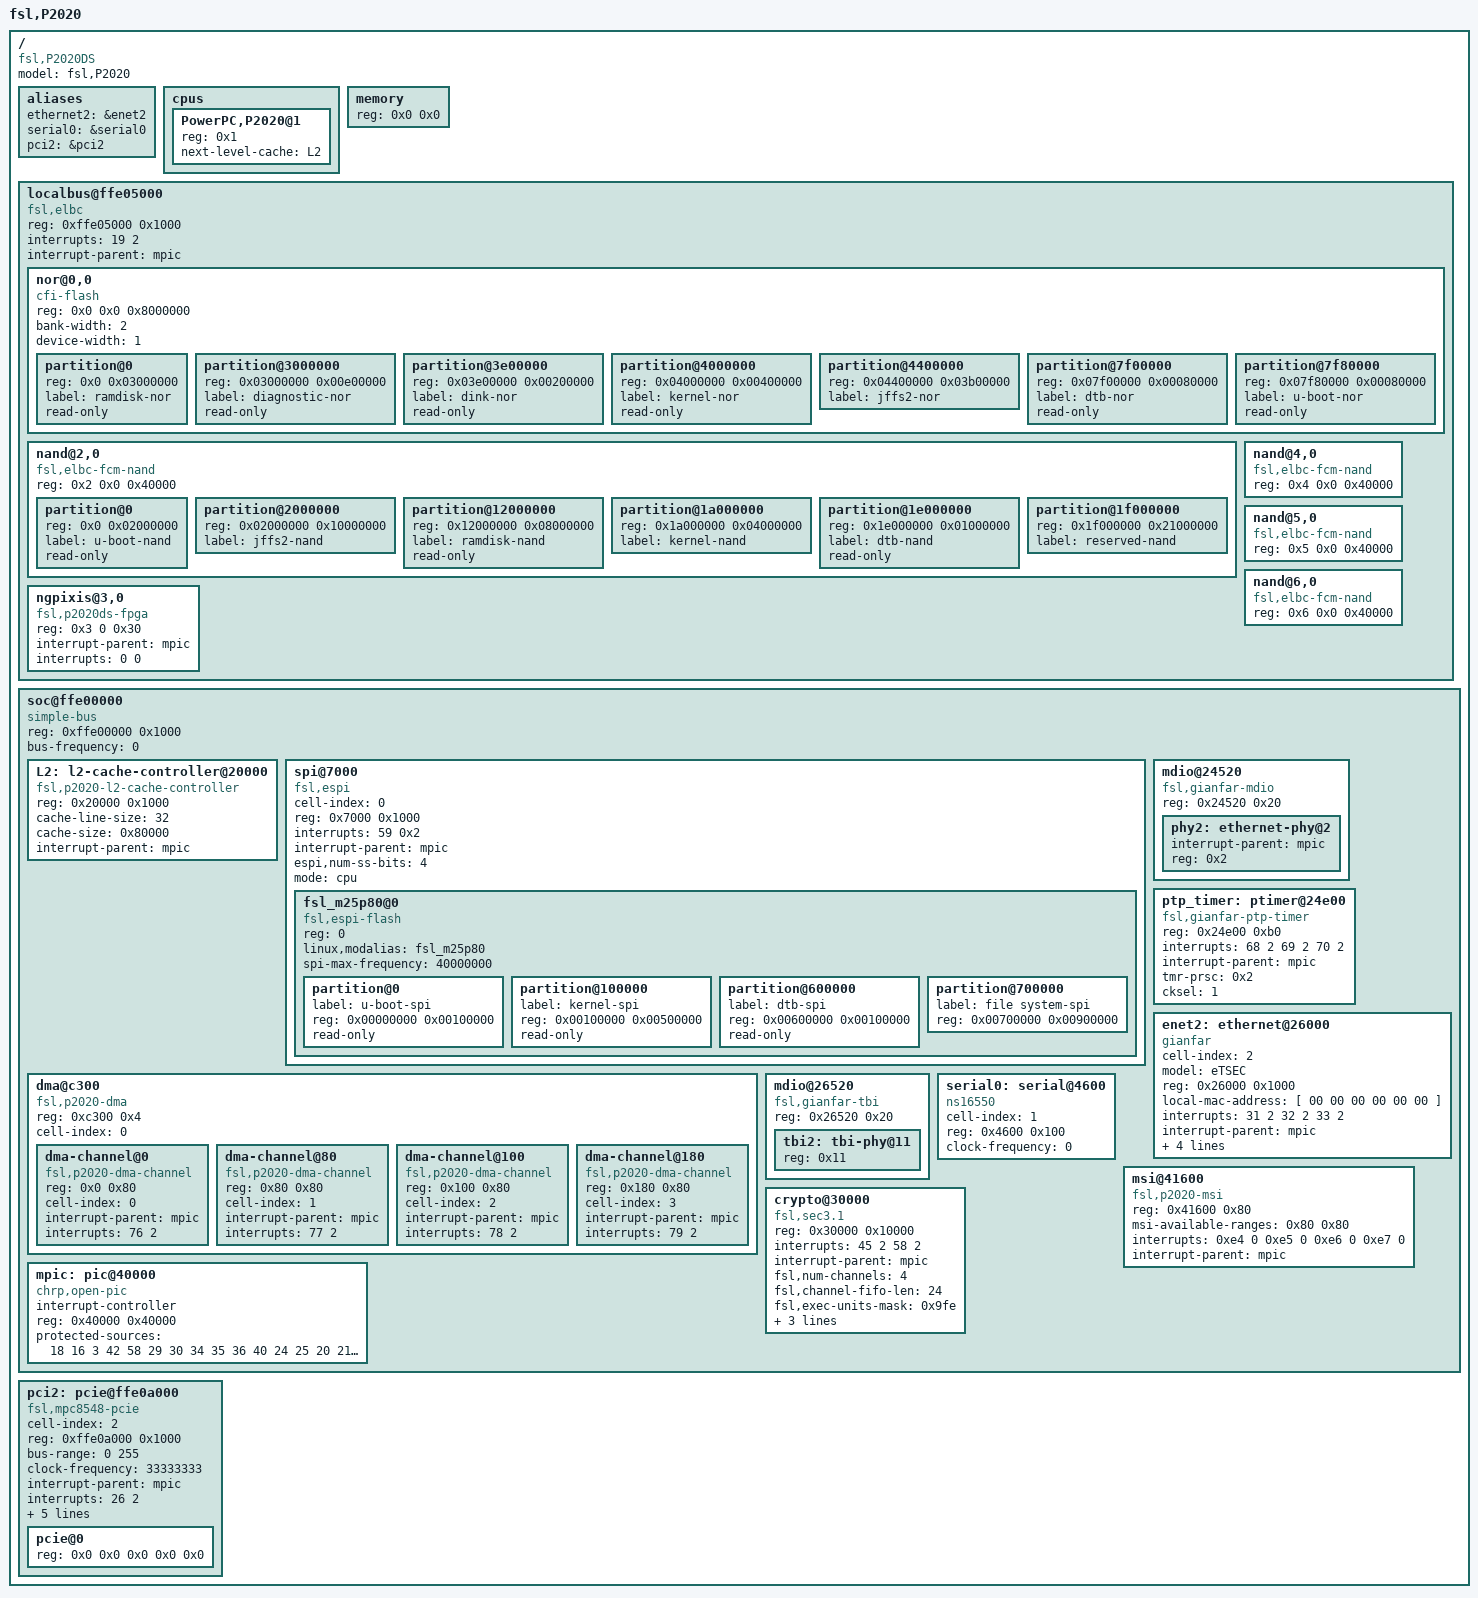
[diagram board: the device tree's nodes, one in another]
/*
 * P2020 DS Core1 Device Tree Source in CAMP mode.
 *
 * In CAMP mode, each core needs to have its own dts. Only mpic and L2 cache
 * can be shared, all the other devices must be assigned to one core only.
 * This dts file allows core1 to have l2, dma2, eth2, eth3, pci2, msi,
 * nor flash and spi.
 *
 * Please note to add "-b 1" for core1's dts compiling.
 *
 * Copyright 2007-2011 Freescale Semiconductor Inc.
 *
 * This program is free software; you can redistribute  it and/or modify it
 * under  the terms of  the GNU General  Public License as published by the
 * Free Software Foundation;  either version 2 of the  License, or (at your
 * option) any later version.
 */

/dts-v1/;
/ {
	model = "fsl,P2020";
	compatible = "fsl,P2020DS", "fsl,P2020DS-CAMP";
	#address-cells = <1>;
	#size-cells = <1>;

	aliases {
		ethernet2 = &enet2;
		serial0 = &serial0;
		pci2 = &pci2;
	};

	cpus {
		#address-cells = <1>;
		#size-cells = <0>;

		PowerPC,P2020@1 {
			device_type = "cpu";
			reg = <0x1>;
			next-level-cache = <&L2>;
		};

	};

	memory {
		device_type = "memory";
		reg = <0x0 0x0>;		// Filled by U-Boot
	};

	localbus@ffe05000 {
		#address-cells = <2>;
		#size-cells = <1>;
		compatible = "fsl,elbc", "simple-bus";
		reg = <0xffe05000 0x1000>;
		interrupts = <19 2>;
		interrupt-parent = <&mpic>;

		ranges = <0x0 0x0 0xe8000000 0x08000000
			  0x1 0x0 0xe0000000 0x08000000
			  0x2 0x0 0xffa00000 0x00040000
			  0x3 0x0 0xffdf0000 0x00008000
			  0x4 0x0 0xffa40000 0x00040000
			  0x5 0x0 0xffa80000 0x00040000
			  0x6 0x0 0xffac0000 0x00040000>;

		nor@0,0 {
			#address-cells = <1>;
			#size-cells = <1>;
			compatible = "cfi-flash";
			reg = <0x0 0x0 0x8000000>;
			bank-width = <2>;
			device-width = <1>;

			partition@0 {
				reg = <0x0 0x03000000>;
				label = "ramdisk-nor";
				read-only;
			};

			partition@3000000 {
				reg = <0x03000000 0x00e00000>;
				label = "diagnostic-nor";
				read-only;
			};

			partition@3e00000 {
				reg = <0x03e00000 0x00200000>;
				label = "dink-nor";
				read-only;
			};

			partition@4000000 {
				reg = <0x04000000 0x00400000>;
				label = "kernel-nor";
				read-only;
			};

			partition@4400000 {
				reg = <0x04400000 0x03b00000>;
				label = "jffs2-nor";
			};

			partition@7f00000 {
				reg = <0x07f00000 0x00080000>;
				label = "dtb-nor";
				read-only;
			};

			partition@7f80000 {
				reg = <0x07f80000 0x00080000>;
				label = "u-boot-nor";
				read-only;
			};
		};

		nand@2,0 {
			#address-cells = <1>;
			#size-cells = <1>;
			compatible = "fsl,elbc-fcm-nand";
			reg = <0x2 0x0 0x40000>;

			partition@0 {
				reg = <0x0 0x02000000>;
				label = "u-boot-nand";
				read-only;
			};

			partition@2000000 {
				reg = <0x02000000 0x10000000>;
				label = "jffs2-nand";
			};

			partition@12000000 {
				reg = <0x12000000 0x08000000>;
				label = "ramdisk-nand";
				read-only;
			};

			partition@1a000000 {
				reg = <0x1a000000 0x04000000>;
				label = "kernel-nand";
			};

			partition@1e000000 {
				reg = <0x1e000000 0x01000000>;
				label = "dtb-nand";
				read-only;
			};

			partition@1f000000 {
				reg = <0x1f000000 0x21000000>;
				label = "reserved-nand";
			};
		};

		nand@4,0 {
			compatible = "fsl,elbc-fcm-nand";
			reg = <0x4 0x0 0x40000>;
		};

		nand@5,0 {
			compatible = "fsl,elbc-fcm-nand";
			reg = <0x5 0x0 0x40000>;
		};

		nand@6,0 {
			compatible = "fsl,elbc-fcm-nand";
			reg = <0x6 0x0 0x40000>;
		};

		ngpixis@3,0 {
			compatible = "fsl,p2020ds-fpga";
			reg = <0x3 0 0x30>;
			interrupt-parent = <&mpic>;
			interrupts = <0 0>;
		};
	};

	soc@ffe00000 {
		#address-cells = <1>;
		#size-cells = <1>;
		device_type = "soc";
		compatible = "simple-bus";
		ranges = <0x0 0xffe00000 0x100000>;
		reg = <0xffe00000 0x1000>;	// CCSRBAR & soc regs, remove once parse code for immrbase fixed
		bus-frequency = <0>;		// Filled out by uboot.

		L2: l2-cache-controller@20000 {
			compatible = "fsl,p2020-l2-cache-controller";
			reg = <0x20000 0x1000>;
			cache-line-size = <32>;	// 32 bytes
			cache-size = <0x80000>;	// L2, 512K
			interrupt-parent = <&mpic>;
		};

		spi@7000 {
			cell-index = <0>;
			#address-cells = <1>;
			#size-cells = <0>;
			compatible = "fsl,espi";
			reg = <0x7000 0x1000>;
			interrupts = <59 0x2>;
			interrupt-parent = <&mpic>;
			espi,num-ss-bits = <4>;
			mode = "cpu";

			fsl_m25p80@0 {
				#address-cells = <1>;
				#size-cells = <1>;
				compatible = "fsl,espi-flash";
				reg = <0>;
				linux,modalias = "fsl_m25p80";
				spi-max-frequency = <40000000>; /* input clock */
				partition@0 {
					label = "u-boot-spi";
					reg = <0x00000000 0x00100000>;
					read-only;
				};
				partition@100000 {
					label = "kernel-spi";
					reg = <0x00100000 0x00500000>;
					read-only;
				};
				partition@600000 {
					label = "dtb-spi";
					reg = <0x00600000 0x00100000>;
					read-only;
				};
				partition@700000 {
					label = "file system-spi";
					reg = <0x00700000 0x00900000>;
				};
			};
		};

		dma@c300 {
			#address-cells = <1>;
			#size-cells = <1>;
			compatible = "fsl,p2020-dma", "fsl,eloplus-dma";
			reg = <0xc300 0x4>;
			ranges = <0x0 0xc100 0x200>;
			cell-index = <0>;
			dma-channel@0 {
				compatible = "fsl,p2020-dma-channel",
						"fsl,eloplus-dma-channel";
				reg = <0x0 0x80>;
				cell-index = <0>;
				interrupt-parent = <&mpic>;
				interrupts = <76 2>;
			};
			dma-channel@80 {
				compatible = "fsl,p2020-dma-channel",
						"fsl,eloplus-dma-channel";
				reg = <0x80 0x80>;
				cell-index = <1>;
				interrupt-parent = <&mpic>;
				interrupts = <77 2>;
			};
			dma-channel@100 {
				compatible = "fsl,p2020-dma-channel",
						"fsl,eloplus-dma-channel";
				reg = <0x100 0x80>;
				cell-index = <2>;
				interrupt-parent = <&mpic>;
				interrupts = <78 2>;
			};
			dma-channel@180 {
				compatible = "fsl,p2020-dma-channel",
						"fsl,eloplus-dma-channel";
				reg = <0x180 0x80>;
				cell-index = <3>;
				interrupt-parent = <&mpic>;
				interrupts = <79 2>;
			};
		};

		mdio@24520 {
			#address-cells = <1>;
			#size-cells = <0>;
			compatible = "fsl,gianfar-mdio";
			reg = <0x24520 0x20>;

			phy2: ethernet-phy@2 {
				interrupt-parent = <&mpic>;
				reg = <0x2>;
			};
		};

		ptp_timer: ptimer@24e00 {
			compatible = "fsl,gianfar-ptp-timer";
			reg = <0x24e00 0xb0>;
			interrupts = <68 2 69 2 70 2>;
			interrupt-parent = <&mpic>;
			tmr-prsc = <0x2>;
			cksel = <1>;
		};

		enet2: ethernet@26000 {
			cell-index = <2>;
			device_type = "network";
			model = "eTSEC";
			compatible = "gianfar";
			reg = <0x26000 0x1000>;
			local-mac-address = [ 00 00 00 00 00 00 ];
			interrupts = <31 2 32 2 33 2>;
			interrupt-parent = <&mpic>;
			tbi-handle = <&tbi2>;
			phy-handle = <&phy2>;
			phy-connection-type = "rgmii-id";
			ptimer-handle = <&ptp_timer>;
		};

		mdio@26520 {
			#address-cells = <1>;
			#size-cells = <0>;
			compatible = "fsl,gianfar-tbi";
			reg = <0x26520 0x20>;

			tbi2: tbi-phy@11 {
				reg = <0x11>;
				device_type = "tbi-phy";
			};
		};

		serial0: serial@4600 {
			cell-index = <1>;
			device_type = "serial";
			compatible = "ns16550";
			reg = <0x4600 0x100>;
			clock-frequency = <0>;
		};

		msi@41600 {
			compatible = "fsl,p2020-msi", "fsl,mpic-msi";
			reg = <0x41600 0x80>;
			msi-available-ranges = <0x80 0x80>;
			interrupts = <
				0xe4 0
				0xe5 0
				0xe6 0
				0xe7 0>;
			interrupt-parent = <&mpic>;
		};

		crypto@30000 {
			compatible = "fsl,sec3.1", "fsl,sec3.0", "fsl,sec2.4",
				     "fsl,sec2.2", "fsl,sec2.1", "fsl,sec2.0";
			reg = <0x30000 0x10000>;
			interrupts = <45 2 58 2>;
			interrupt-parent = <&mpic>;
			fsl,num-channels = <4>;
			fsl,channel-fifo-len = <24>;
			fsl,exec-units-mask = <0x9fe>;
			fsl,descriptor-types-mask = <0x3ab0ebf>;
			fsl,multi-host-mode = "primary";
			fsl,channel-remap = <0x3>;
		};

		mpic: pic@40000 {
			interrupt-controller;
			#address-cells = <0>;
			#interrupt-cells = <2>;
			reg = <0x40000 0x40000>;
			compatible = "chrp,open-pic";
			device_type = "open-pic";
			protected-sources = <
			18 16 3 42 58		/* MEM L2 mdio serial */
			29 30 34 35 36 40	/* eth0 eth1*/
			24 25 20 21 22 23	/* pci0 pci1 dma1 */
			43 28 72		/* i2c usb esdhc */
			0x9 0xa			/* pci slot */
			0x6 0x7 0xe 0x5		/* Audio elgacy SATA */
			48 49 50 53 54 55 56	/* rapidio */
			0xe0 0xe1 0xe2 0xe3     /* msi */
			>;
		};
	};

	pci2: pcie@ffe0a000 {
		cell-index = <2>;
		compatible = "fsl,mpc8548-pcie";
		device_type = "pci";
		#interrupt-cells = <1>;
		#size-cells = <2>;
		#address-cells = <3>;
		reg = <0xffe0a000 0x1000>;
		bus-range = <0 255>;
		ranges = <0x2000000 0x0 0xc0000000 0xc0000000 0x0 0x20000000
			  0x1000000 0x0 0x0 0xffc20000 0x0 0x10000>;
		clock-frequency = <33333333>;
		interrupt-parent = <&mpic>;
		interrupts = <26 2>;
		interrupt-map-mask = <0xf800 0x0 0x0 0x7>;
		interrupt-map = <
			/* IDSEL 0x0 */
			0000 0x0 0x0 0x1 &mpic 0x0 0x1
			0000 0x0 0x0 0x2 &mpic 0x1 0x1
			0000 0x0 0x0 0x3 &mpic 0x2 0x1
			0000 0x0 0x0 0x4 &mpic 0x3 0x1
			>;
		pcie@0 {
			reg = <0x0 0x0 0x0 0x0 0x0>;
			#size-cells = <2>;
			#address-cells = <3>;
			device_type = "pci";
			ranges = <0x2000000 0x0 0xc0000000
				  0x2000000 0x0 0xc0000000
				  0x0 0x20000000

				  0x1000000 0x0 0x0
				  0x1000000 0x0 0x0
				  0x0 0x10000>;
		};
	};
};
